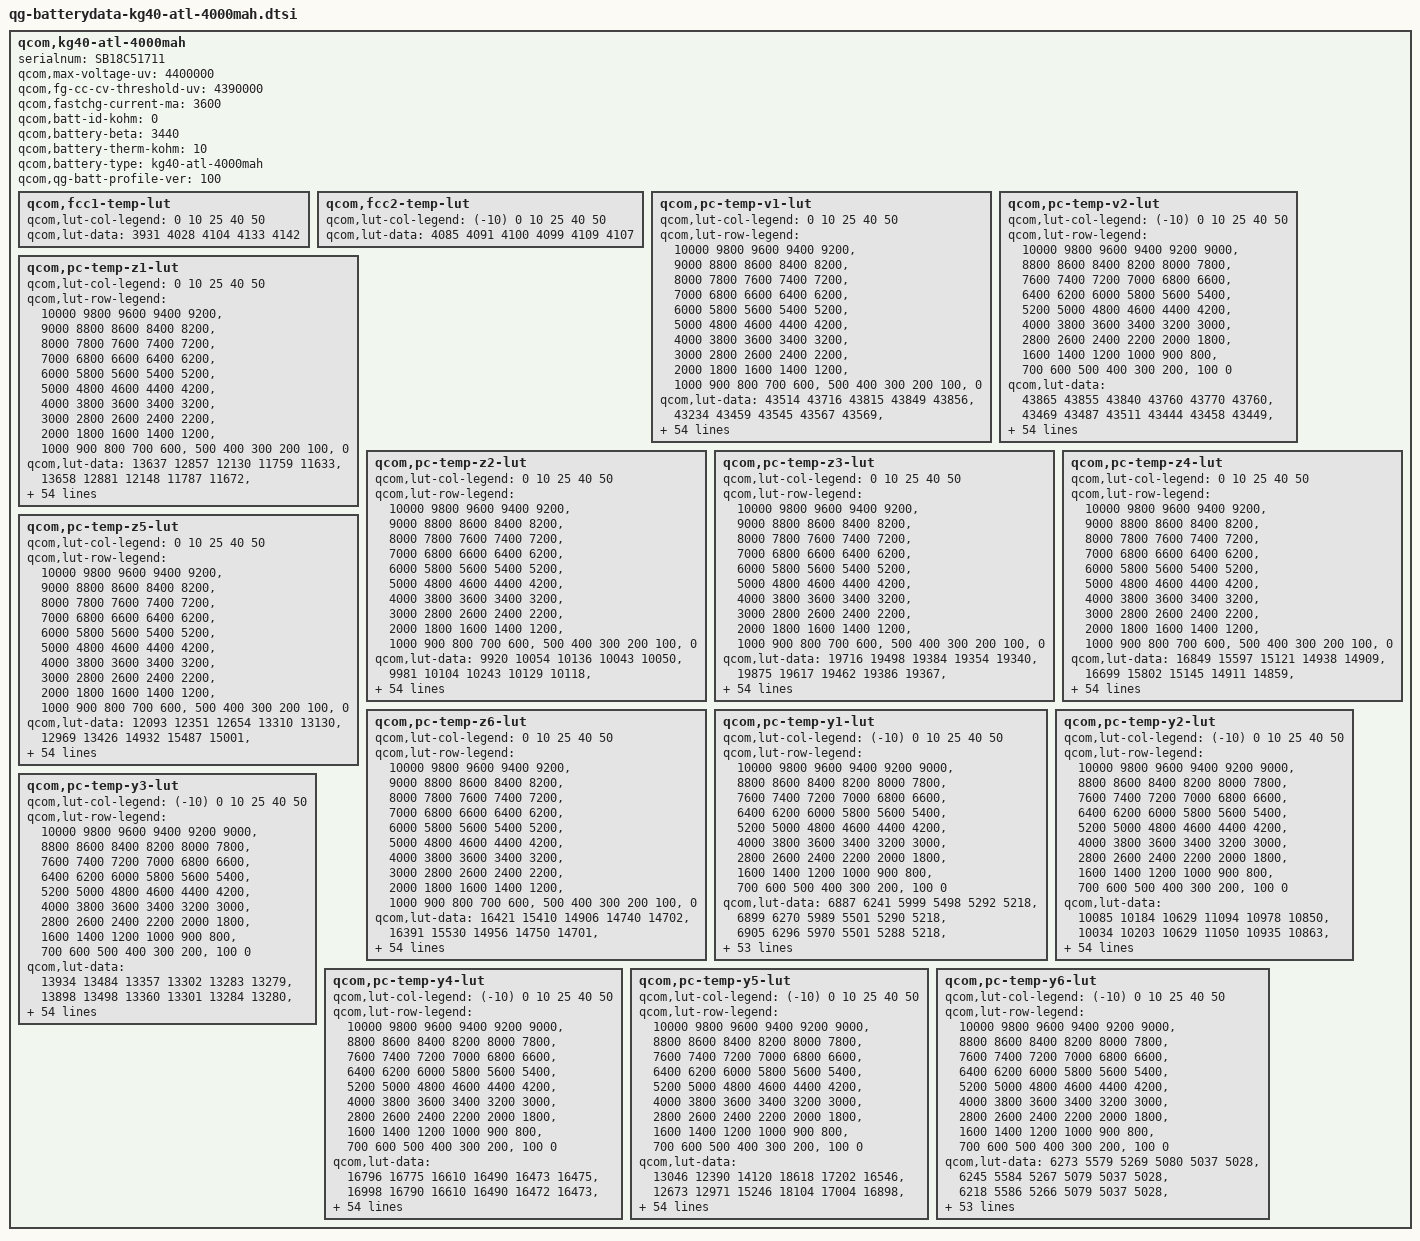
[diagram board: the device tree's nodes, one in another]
qcom,kg40-atl-4000mah {
    /* 4123835_Huaqin_QL1883_ATL_4000mAH_PMI632_averaged_MasterSlave_Aug13th2019 */
    serialnum = "SB18C51711";
    qcom,max-voltage-uv = <4400000>;
    qcom,fg-cc-cv-threshold-uv = <4390000>;
    qcom,fastchg-current-ma = <3600>;
    qcom,batt-id-kohm = <0>;
    qcom,battery-beta = <3440>;
    qcom,battery-therm-kohm = <10>;
    qcom,battery-type = "kg40-atl-4000mah";
    qcom,qg-batt-profile-ver = <100>;

	qcom,fcc1-temp-lut {
		qcom,lut-col-legend = <0 10 25 40 50>;
		qcom,lut-data = <3931 4028 4104 4133 4142>;
	};

	qcom,fcc2-temp-lut {
		qcom,lut-col-legend = <(-10) 0 10 25 40 50>;
		qcom,lut-data = <4085 4091 4100 4099 4109 4107>;
	};

	qcom,pc-temp-v1-lut {
		qcom,lut-col-legend = <0 10 25 40 50>;
		qcom,lut-row-legend = <10000 9800 9600 9400 9200>,
			<9000 8800 8600 8400 8200>,
			<8000 7800 7600 7400 7200>,
			<7000 6800 6600 6400 6200>,
			<6000 5800 5600 5400 5200>,
			<5000 4800 4600 4400 4200>,
			<4000 3800 3600 3400 3200>,
			<3000 2800 2600 2400 2200>,
			<2000 1800 1600 1400 1200>,
			<1000 900 800 700 600>,
			<500 400 300 200 100>,
			<0>;
		qcom,lut-data = <43514 43716 43815 43849 43856>,
			<43234 43459 43545 43567 43569>,
			<42974 43194 43286 43323 43320>,
			<42734 42937 43040 43079 43083>,
			<42503 42695 42797 42835 42850>,
			<42274 42459 42556 42597 42613>,
			<42047 42226 42319 42362 42377>,
			<41826 41997 42085 42129 42144>,
			<41605 41772 41854 41899 41915>,
			<41393 41547 41629 41672 41688>,
			<41204 41330 41406 41446 41463>,
			<41033 41139 41191 41227 41243>,
			<40840 40969 40987 41018 41028>,
			<40580 40774 40789 40820 40820>,
			<40311 40523 40582 40618 40617>,
			<40109 40273 40365 40407 40417>,
			<39945 40088 40168 40206 40226>,
			<39799 39933 40000 40034 40051>,
			<39663 39788 39846 39877 39887>,
			<39536 39654 39701 39723 39730>,
			<39409 39521 39565 39580 39584>,
			<39284 39373 39394 39415 39421>,
			<39160 39217 39128 39165 39182>,
			<39039 39038 38871 38900 38923>,
			<38919 38806 38722 38746 38764>,
			<38795 38605 38612 38645 38660>,
			<38659 38499 38522 38555 38566>,
			<38538 38425 38449 38467 38474>,
			<38447 38366 38385 38386 38388>,
			<38370 38320 38322 38310 38302>,
			<38313 38280 38265 38239 38219>,
			<38268 38241 38212 38173 38147>,
			<38231 38205 38162 38116 38086>,
			<38199 38171 38115 38061 38029>,
			<38172 38140 38075 38011 37974>,
			<38143 38109 38036 37964 37922>,
			<38117 38077 37996 37916 37868>,
			<38085 38043 37955 37871 37815>,
			<38037 37993 37902 37814 37751>,
			<37966 37913 37820 37729 37663>,
			<37878 37814 37719 37625 37557>,
			<37760 37698 37609 37516 37446>,
			<37623 37563 37483 37394 37322>,
			<37471 37405 37327 37238 37166>,
			<37329 37262 37181 37093 37026>,
			<37226 37160 37082 37002 36943>,
			<37193 37131 37054 36971 36915>,
			<37177 37111 37033 36953 36894>,
			<37149 37091 37017 36933 36872>,
			<37105 37051 36975 36877 36805>,
			<36909 36846 36750 36632 36537>,
			<36470 36417 36324 36196 36096>,
			<35894 35844 35752 35620 35518>,
			<35109 35058 34971 34835 34728>,
			<33864 33824 33754 33616 33501>,
			<30000 30000 30000 30000 30000>;
	};

	qcom,pc-temp-v2-lut {
		qcom,lut-col-legend = <(-10) 0 10 25 40 50>;
		qcom,lut-row-legend = <10000 9800 9600 9400 9200 9000>,
			<8800 8600 8400 8200 8000 7800>,
			<7600 7400 7200 7000 6800 6600>,
			<6400 6200 6000 5800 5600 5400>,
			<5200 5000 4800 4600 4400 4200>,
			<4000 3800 3600 3400 3200 3000>,
			<2800 2600 2400 2200 2000 1800>,
			<1600 1400 1200 1000 900 800>,
			<700 600 500 400 300 200>,
			<100 0>;
		qcom,lut-data = <43865 43855 43840 43760 43770 43760>,
			<43469 43487 43511 43444 43458 43449>,
			<43114 43156 43207 43152 43168 43160>,
			<42803 42867 42933 42886 42904 42898>,
			<42528 42616 42686 42645 42663 42659>,
			<42282 42372 42445 42409 42427 42423>,
			<42071 42128 42202 42173 42191 42188>,
			<41868 41889 41965 41940 41957 41955>,
			<41619 41657 41735 41711 41728 41726>,
			<41337 41430 41511 41484 41501 41499>,
			<41120 41218 41296 41264 41278 41276>,
			<40992 41027 41092 41051 41061 41058>,
			<40858 40839 40890 40842 40849 40844>,
			<40597 40639 40685 40636 40645 40641>,
			<40215 40429 40476 40430 40445 40443>,
			<39898 40181 40267 40229 40252 40252>,
			<39645 39854 40058 40028 40061 40066>,
			<39428 39563 39848 39846 39880 39889>,
			<39251 39386 39632 39702 39721 39725>,
			<39097 39247 39417 39571 39568 39566>,
			<38943 39092 39217 39390 39389 39391>,
			<38787 38923 39026 39139 39183 39198>,
			<38640 38767 38855 38911 38983 39006>,
			<38497 38638 38703 38737 38787 38804>,
			<38364 38517 38567 38588 38610 38616>,
			<38264 38385 38446 38464 38477 38480>,
			<38185 38240 38338 38360 38371 38373>,
			<38115 38129 38240 38265 38276 38277>,
			<38051 38055 38150 38175 38190 38190>,
			<37990 37996 38067 38094 38112 38111>,
			<37934 37944 37987 38022 38043 38038>,
			<37882 37898 37913 37954 37978 37969>,
			<37830 37858 37857 37895 37915 37906>,
			<37778 37824 37816 37841 37854 37849>,
			<37725 37788 37780 37791 37790 37787>,
			<37668 37741 37743 37739 37718 37701>,
			<37606 37685 37706 37686 37641 37602>,
			<37543 37627 37664 37628 37562 37508>,
			<37476 37570 37617 37561 37479 37418>,
			<37408 37505 37560 37488 37396 37332>,
			<37341 37427 37477 37407 37317 37252>,
			<37274 37334 37374 37314 37229 37165>,
			<37204 37226 37258 37199 37120 37055>,
			<37134 37108 37123 37066 36988 36923>,
			<37057 36989 36979 36940 36872 36812>,
			<36956 36881 36891 36880 36822 36766>,
			<36905 36840 36864 36862 36809 36753>,
			<36845 36798 36836 36847 36794 36740>,
			<36772 36747 36799 36818 36766 36710>,
			<36659 36671 36728 36738 36680 36605>,
			<36440 36485 36524 36476 36391 36288>,
			<36056 36086 36073 35978 35895 35783>,
			<35473 35476 35371 35342 35248 35131>,
			<34595 34618 34504 34471 34366 34243>,
			<33198 33316 33251 33249 33151 33010>,
			<28298 28054 28063 28066 28079 27986>;
	};

	qcom,pc-temp-z1-lut {
		qcom,lut-col-legend = <0 10 25 40 50>;
		qcom,lut-row-legend = <10000 9800 9600 9400 9200>,
			<9000 8800 8600 8400 8200>,
			<8000 7800 7600 7400 7200>,
			<7000 6800 6600 6400 6200>,
			<6000 5800 5600 5400 5200>,
			<5000 4800 4600 4400 4200>,
			<4000 3800 3600 3400 3200>,
			<3000 2800 2600 2400 2200>,
			<2000 1800 1600 1400 1200>,
			<1000 900 800 700 600>,
			<500 400 300 200 100>,
			<0>;
		qcom,lut-data = <13637 12857 12130 11759 11633>,
			<13658 12881 12148 11787 11672>,
			<13662 12861 12139 11782 11670>,
			<13657 12850 12126 11777 11669>,
			<13653 12843 12114 11773 11669>,
			<13648 12834 12104 11769 11667>,
			<13630 12822 12094 11765 11664>,
			<13621 12797 12085 11764 11664>,
			<13627 12782 12076 11763 11667>,
			<13634 12776 12073 11762 11669>,
			<13627 12772 12073 11762 11669>,
			<13601 12769 12072 11762 11668>,
			<13573 12762 12072 11761 11668>,
			<13539 12754 12071 11761 11668>,
			<13503 12735 12069 11760 11669>,
			<13482 12719 12066 11760 11668>,
			<13468 12721 12064 11759 11668>,
			<13461 12730 12067 11760 11669>,
			<13457 12737 12071 11762 11672>,
			<13452 12744 12075 11765 11674>,
			<13450 12749 12079 11767 11676>,
			<13451 12753 12082 11769 11678>,
			<13455 12759 12084 11770 11679>,
			<13473 12763 12087 11771 11679>,
			<13499 12767 12092 11773 11681>,
			<13509 12772 12098 11777 11683>,
			<13514 12775 12103 11780 11685>,
			<13518 12776 12109 11784 11688>,
			<13523 12780 12114 11788 11692>,
			<13527 12786 12119 11792 11696>,
			<13526 12792 12124 11796 11700>,
			<13528 12794 12129 11801 11704>,
			<13532 12793 12136 11805 11708>,
			<13534 12797 12143 11810 11713>,
			<13539 12804 12149 11815 11718>,
			<13549 12812 12155 11821 11723>,
			<13564 12822 12162 11825 11726>,
			<13580 12836 12170 11829 11728>,
			<13595 12843 12178 11833 11730>,
			<13616 12848 12186 11836 11733>,
			<13632 12853 12193 11840 11737>,
			<13631 12871 12204 11843 11741>,
			<13628 12890 12215 11848 11745>,
			<13631 12895 12218 11853 11748>,
			<13636 12905 12223 11860 11750>,
			<13626 12899 12232 11863 11753>,
			<13650 12879 12233 11862 11753>,
			<13630 12918 12230 11863 11754>,
			<13614 12896 12231 11866 11757>,
			<13636 12907 12241 11871 11762>,
			<13683 12912 12250 11876 11767>,
			<13645 12946 12265 11886 11774>,
			<13664 12980 12283 11900 11788>,
			<13708 13028 12309 11918 11804>,
			<13708 13028 12309 11918 11804>,
			<13708 13028 12309 11918 11804>;
	};

	qcom,pc-temp-z2-lut {
		qcom,lut-col-legend = <0 10 25 40 50>;
		qcom,lut-row-legend = <10000 9800 9600 9400 9200>,
			<9000 8800 8600 8400 8200>,
			<8000 7800 7600 7400 7200>,
			<7000 6800 6600 6400 6200>,
			<6000 5800 5600 5400 5200>,
			<5000 4800 4600 4400 4200>,
			<4000 3800 3600 3400 3200>,
			<3000 2800 2600 2400 2200>,
			<2000 1800 1600 1400 1200>,
			<1000 900 800 700 600>,
			<500 400 300 200 100>,
			<0>;
		qcom,lut-data = <9920 10054 10136 10043 10050>,
			<9981 10104 10243 10129 10118>,
			<10031 10086 10266 10237 10252>,
			<10078 10069 10257 10280 10262>,
			<10109 10048 10245 10299 10263>,
			<10117 10027 10218 10287 10254>,
			<10120 10019 10189 10262 10236>,
			<10120 10013 10166 10243 10221>,
			<10113 10009 10145 10220 10200>,
			<10101 10004 10142 10208 10186>,
			<10091 10001 10157 10213 10156>,
			<10081 10026 10176 10215 10115>,
			<10067 10109 10193 10180 10117>,
			<10023 10146 10209 10102 10137>,
			<9977 10094 10216 10076 10149>,
			<9984 10037 10219 10130 10120>,
			<10043 10044 10222 10179 10091>,
			<10079 10073 10227 10162 10098>,
			<10049 10098 10234 10126 10113>,
			<9999 10119 10246 10120 10128>,
			<9981 10137 10267 10141 10149>,
			<9972 10152 10293 10177 10177>,
			<9968 10164 10337 10289 10249>,
			<9967 10174 10370 10422 10338>,
			<9967 10184 10353 10405 10338>,
			<9969 10191 10307 10260 10265>,
			<9982 10195 10295 10190 10226>,
			<9993 10198 10316 10205 10237>,
			<9998 10198 10333 10232 10260>,
			<10002 10193 10334 10273 10322>,
			<10005 10188 10334 10333 10444>,
			<10010 10189 10337 10356 10479>,
			<10016 10193 10349 10360 10385>,
			<10021 10197 10358 10358 10270>,
			<10027 10204 10360 10338 10192>,
			<10034 10212 10361 10306 10128>,
			<10045 10220 10366 10294 10124>,
			<10056 10227 10379 10299 10175>,
			<10067 10235 10395 10306 10229>,
			<10077 10242 10423 10324 10272>,
			<10089 10250 10446 10346 10305>,
			<10102 10257 10445 10349 10309>,
			<10120 10265 10437 10347 10305>,
			<10152 10277 10437 10383 10319>,
			<10355 10367 10455 10411 10325>,
			<10447 10450 10501 10357 10270>,
			<10434 10469 10494 10327 10287>,
			<10397 10559 10492 10341 10289>,
			<10413 10625 10481 10358 10306>,
			<10454 10627 10532 10440 10367>,
			<10417 10605 10584 10398 10252>,
			<10323 10588 10532 10222 10072>,
			<10117 10479 10437 10136 9996>,
			<9928 10350 10431 10083 9941>,
			<9928 10350 10431 10083 9941>,
			<9928 10350 10431 10083 9941>;
	};

	qcom,pc-temp-z3-lut {
		qcom,lut-col-legend = <0 10 25 40 50>;
		qcom,lut-row-legend = <10000 9800 9600 9400 9200>,
			<9000 8800 8600 8400 8200>,
			<8000 7800 7600 7400 7200>,
			<7000 6800 6600 6400 6200>,
			<6000 5800 5600 5400 5200>,
			<5000 4800 4600 4400 4200>,
			<4000 3800 3600 3400 3200>,
			<3000 2800 2600 2400 2200>,
			<2000 1800 1600 1400 1200>,
			<1000 900 800 700 600>,
			<500 400 300 200 100>,
			<0>;
		qcom,lut-data = <19716 19498 19384 19354 19340>,
			<19875 19617 19462 19386 19367>,
			<19914 19691 19504 19420 19409>,
			<19868 19717 19515 19441 19419>,
			<19812 19714 19518 19450 19424>,
			<19776 19710 19517 19452 19431>,
			<19745 19705 19514 19453 19437>,
			<19735 19696 19511 19451 19438>,
			<19737 19688 19507 19445 19431>,
			<19739 19682 19501 19438 19424>,
			<19740 19677 19486 19432 19418>,
			<19740 19672 19475 19426 19412>,
			<19745 19670 19471 19416 19407>,
			<19780 19669 19468 19401 19404>,
			<19830 19655 19467 19397 19400>,
			<19865 19634 19468 19402 19397>,
			<19894 19611 19467 19407 19393>,
			<19907 19580 19459 19402 19387>,
			<19857 19563 19447 19391 19377>,
			<19783 19555 19440 19383 19370>,
			<19769 19551 19434 19376 19363>,
			<19778 19557 19432 19373 19360>,
			<19786 19576 19450 19381 19364>,
			<19790 19592 19468 19393 19372>,
			<19796 19607 19464 19390 19368>,
			<19803 19616 19451 19369 19347>,
			<19814 19616 19445 19360 19335>,
			<19821 19615 19442 19360 19339>,
			<19818 19612 19440 19361 19346>,
			<19811 19606 19441 19366 19364>,
			<19805 19598 19443 19379 19398>,
			<19794 19592 19445 19390 19409>,
			<19782 19585 19451 19399 19404>,
			<19770 19580 19454 19404 19396>,
			<19756 19576 19454 19402 19388>,
			<19741 19572 19452 19397 19378>,
			<19723 19565 19450 19391 19372>,
			<19707 19558 19445 19383 19367>,
			<19700 19553 19441 19378 19363>,
			<19696 19550 19438 19375 19358>,
			<19691 19547 19435 19373 19355>,
			<19684 19543 19431 19370 19356>,
			<19673 19539 19425 19367 19359>,
			<19647 19532 19423 19371 19367>,
			<19559 19498 19414 19373 19370>,
			<19508 19464 19400 19356 19352>,
			<19498 19453 19394 19355 19343>,
			<19349 19414 19392 19349 19337>,
			<19344 19358 19367 19342 19333>,
			<19336 19378 19359 19336 19332>,
			<19346 19389 19370 19342 19354>,
			<19355 19374 19364 19365 19367>,
			<19362 19351 19364 19368 19370>,
			<19367 19345 19351 19369 19372>,
			<19367 19345 19351 19369 19372>,
			<19367 19345 19351 19369 19372>;
	};

	qcom,pc-temp-z4-lut {
		qcom,lut-col-legend = <0 10 25 40 50>;
		qcom,lut-row-legend = <10000 9800 9600 9400 9200>,
			<9000 8800 8600 8400 8200>,
			<8000 7800 7600 7400 7200>,
			<7000 6800 6600 6400 6200>,
			<6000 5800 5600 5400 5200>,
			<5000 4800 4600 4400 4200>,
			<4000 3800 3600 3400 3200>,
			<3000 2800 2600 2400 2200>,
			<2000 1800 1600 1400 1200>,
			<1000 900 800 700 600>,
			<500 400 300 200 100>,
			<0>;
		qcom,lut-data = <16849 15597 15121 14938 14909>,
			<16699 15802 15145 14911 14859>,
			<16517 15603 15206 14985 14923>,
			<16281 15414 15085 14939 14894>,
			<16052 15276 14994 14885 14856>,
			<15885 15158 14940 14853 14828>,
			<15748 15073 14898 14826 14803>,
			<15629 15005 14862 14802 14782>,
			<15527 14953 14833 14779 14763>,
			<15435 14914 14812 14765 14751>,
			<15350 14879 14796 14757 14746>,
			<15271 14833 14783 14751 14743>,
			<15200 14775 14769 14749 14737>,
			<15140 14752 14756 14746 14729>,
			<15081 14772 14747 14743 14723>,
			<14998 14796 14741 14732 14718>,
			<14884 14796 14734 14720 14713>,
			<14829 14792 14724 14711 14709>,
			<14847 14787 14713 14704 14704>,
			<14874 14771 14706 14701 14701>,
			<14873 14755 14700 14699 14697>,
			<14841 14744 14701 14698 14695>,
			<14813 14736 14767 14753 14745>,
			<14800 14738 14839 14838 14831>,
			<14790 14802 14857 14860 14856>,
			<14789 14863 14867 14866 14863>,
			<14801 14862 14868 14868 14865>,
			<14812 14852 14853 14856 14851>,
			<14817 14840 14832 14835 14823>,
			<14822 14824 14814 14812 14787>,
			<14822 14807 14796 14784 14739>,
			<14816 14793 14777 14759 14715>,
			<14807 14780 14759 14734 14705>,
			<14799 14767 14743 14717 14701>,
			<14791 14755 14730 14710 14701>,
			<14787 14745 14719 14706 14700>,
			<14784 14737 14714 14705 14700>,
			<14782 14731 14710 14705 14700>,
			<14775 14729 14708 14705 14701>,
			<14765 14731 14715 14715 14713>,
			<14760 14732 14721 14728 14730>,
			<14760 14730 14720 14727 14727>,
			<14760 14727 14714 14720 14715>,
			<14763 14725 14713 14718 14712>,
			<14762 14717 14707 14710 14706>,
			<14767 14706 14681 14690 14686>,
			<14777 14710 14678 14684 14685>,
			<14938 14743 14665 14672 14673>,
			<14937 14800 14679 14654 14649>,
			<14938 14770 14681 14653 14641>,
			<14925 14768 14693 14685 14664>,
			<14940 14802 14714 14679 14670>,
			<14951 14837 14722 14680 14672>,
			<14969 14854 14741 14684 14673>,
			<14969 14854 14741 14684 14673>,
			<14969 14854 14741 14684 14673>;
	};

	qcom,pc-temp-z5-lut {
		qcom,lut-col-legend = <0 10 25 40 50>;
		qcom,lut-row-legend = <10000 9800 9600 9400 9200>,
			<9000 8800 8600 8400 8200>,
			<8000 7800 7600 7400 7200>,
			<7000 6800 6600 6400 6200>,
			<6000 5800 5600 5400 5200>,
			<5000 4800 4600 4400 4200>,
			<4000 3800 3600 3400 3200>,
			<3000 2800 2600 2400 2200>,
			<2000 1800 1600 1400 1200>,
			<1000 900 800 700 600>,
			<500 400 300 200 100>,
			<0>;
		qcom,lut-data = <12093 12351 12654 13310 13130>,
			<12969 13426 14932 15487 15001>,
			<13227 14458 15741 15878 16983>,
			<13194 15123 16257 17020 17637>,
			<13163 15442 16621 18115 18105>,
			<13173 15692 16913 18550 18998>,
			<13213 16011 17205 18846 19992>,
			<13261 16367 17620 19106 20468>,
			<13380 16784 18082 19427 20753>,
			<13524 17458 18245 19586 20885>,
			<13610 18064 18246 19735 20781>,
			<13696 18218 18275 19799 20670>,
			<13857 18274 18647 19281 20900>,
			<14557 18440 19343 18248 21371>,
			<15757 19772 19999 18014 21894>,
			<17422 21116 20700 19927 22742>,
			<20012 20497 21239 21817 23430>,
			<21355 18511 21639 21987 23239>,
			<19807 17762 22072 21837 22663>,
			<17469 18300 22678 21981 22506>,
			<17275 19388 23813 22265 22756>,
			<18927 22541 26024 22744 23168>,
			<21004 29413 36255 25704 24161>,
			<23157 35883 45752 29567 25405>,
			<25990 43009 42174 28416 24421>,
			<29841 47676 31641 21465 18772>,
			<36608 46180 26136 17467 15562>,
			<41902 41642 23773 16631 15324>,
			<42493 37881 22617 16227 15218>,
			<41188 34834 22445 16559 16795>,
			<39462 32444 22443 17797 21656>,
			<37013 30832 22892 19446 24573>,
			<34356 29619 24990 22230 25951>,
			<32102 29327 27334 24968 26686>,
			<29927 29423 29634 27092 26841>,
			<27798 29497 31701 28799 26915>,
			<25272 29152 32555 28975 26904>,
			<23535 28486 33059 28276 26856>,
			<23746 28225 33190 27344 26755>,
			<24683 28341 32153 26165 24895>,
			<25192 28353 30364 24671 22301>,
			<25285 27871 28104 22689 21475>,
			<25162 27189 25680 20617 21114>,
			<23356 26485 25130 21603 22764>,
			<20381 24508 24623 22471 24060>,
			<18034 22141 24703 19962 20088>,
			<17562 20154 23046 19951 17960>,
			<12058 15796 23408 19357 17858>,
			<11979 13106 17961 20069 19972>,
			<11907 14047 17176 19187 21295>,
			<12188 14740 17659 16669 20488>,
			<12165 13503 15607 17584 19434>,
			<12056 12586 14938 17202 18529>,
			<11882 12243 13660 16338 17231>,
			<11882 12243 13660 16338 17231>,
			<11882 12243 13660 16338 17231>;
	};

	qcom,pc-temp-z6-lut {
		qcom,lut-col-legend = <0 10 25 40 50>;
		qcom,lut-row-legend = <10000 9800 9600 9400 9200>,
			<9000 8800 8600 8400 8200>,
			<8000 7800 7600 7400 7200>,
			<7000 6800 6600 6400 6200>,
			<6000 5800 5600 5400 5200>,
			<5000 4800 4600 4400 4200>,
			<4000 3800 3600 3400 3200>,
			<3000 2800 2600 2400 2200>,
			<2000 1800 1600 1400 1200>,
			<1000 900 800 700 600>,
			<500 400 300 200 100>,
			<0>;
		qcom,lut-data = <16421 15410 14906 14740 14702>,
			<16391 15530 14956 14750 14701>,
			<16329 15470 15001 14797 14748>,
			<16181 15403 14954 14786 14740>,
			<16016 15335 14916 14773 14730>,
			<15907 15268 14890 14761 14722>,
			<15817 15218 14868 14749 14715>,
			<15746 15177 14850 14737 14707>,
			<15692 15145 14834 14725 14697>,
			<15646 15120 14819 14715 14688>,
			<15599 15098 14805 14708 14682>,
			<15554 15071 14794 14702 14677>,
			<15520 15041 14784 14694 14671>,
			<15500 15026 14777 14686 14665>,
			<15483 15022 14772 14680 14660>,
			<15460 15018 14769 14678 14656>,
			<15430 15009 14765 14675 14652>,
			<15402 14993 14756 14669 14646>,
			<15377 14979 14746 14660 14639>,
			<15357 14969 14739 14654 14633>,
			<15347 14962 14734 14649 14628>,
			<15340 14963 14734 14647 14625>,
			<15338 14971 14773 14677 14650>,
			<15338 14983 14814 14720 14691>,
			<15340 15019 14816 14726 14698>,
			<15343 15050 14816 14720 14693>,
			<15356 15051 14816 14714 14687>,
			<15368 15047 14809 14709 14681>,
			<15370 15043 14800 14703 14675>,
			<15370 15034 14794 14698 14672>,
			<15368 15024 14788 14693 14669>,
			<15362 15016 14782 14688 14665>,
			<15355 15009 14778 14684 14659>,
			<15348 15003 14774 14679 14653>,
			<15340 14998 14770 14675 14649>,
			<15333 14993 14766 14672 14645>,
			<15326 14989 14762 14668 14641>,
			<15321 14986 14759 14664 14638>,
			<15320 14985 14758 14662 14636>,
			<15319 14988 14761 14665 14640>,
			<15319 14990 14763 14669 14644>,
			<15322 14991 14762 14668 14644>,
			<15323 14992 14758 14664 14642>,
			<15317 14992 14758 14666 14644>,
			<15286 14980 14753 14664 14644>,
			<15268 14962 14737 14647 14626>,
			<15265 14957 14733 14644 14622>,
			<15257 14952 14727 14636 14613>,
			<15256 14949 14719 14625 14600>,
			<15258 14950 14718 14621 14596>,
			<15266 14958 14731 14639 14619>,
			<15284 14974 14741 14652 14632>,
			<15308 14987 14749 14658 14638>,
			<15345 15009 14758 14664 14644>,
			<15345 15009 14758 14664 14644>,
			<15345 15009 14758 14664 14644>;
	};

	qcom,pc-temp-y1-lut {
		qcom,lut-col-legend = <(-10) 0 10 25 40 50>;
		qcom,lut-row-legend = <10000 9800 9600 9400 9200 9000>,
			<8800 8600 8400 8200 8000 7800>,
			<7600 7400 7200 7000 6800 6600>,
			<6400 6200 6000 5800 5600 5400>,
			<5200 5000 4800 4600 4400 4200>,
			<4000 3800 3600 3400 3200 3000>,
			<2800 2600 2400 2200 2000 1800>,
			<1600 1400 1200 1000 900 800>,
			<700 600 500 400 300 200>,
			<100 0>;
		qcom,lut-data = <6887 6241 5999 5498 5292 5218>,
			<6899 6270 5989 5501 5290 5218>,
			<6905 6296 5970 5501 5288 5218>,
			<6906 6316 5948 5499 5286 5218>,
			<6905 6330 5931 5496 5284 5218>,
			<6904 6334 5925 5491 5282 5217>,
			<6895 6326 5925 5484 5280 5216>,
			<6884 6317 5926 5477 5277 5215>,
			<6883 6319 5925 5475 5276 5215>,
			<6882 6332 5924 5473 5275 5216>,
			<6876 6335 5921 5472 5275 5216>,
			<6855 6324 5915 5470 5274 5216>,
			<6835 6314 5910 5469 5273 5216>,
			<6846 6322 5911 5468 5273 5215>,
			<6876 6340 5915 5467 5272 5215>,
			<6886 6346 5916 5468 5273 5215>,
			<6883 6345 5912 5470 5273 5216>,
			<6879 6343 5911 5472 5274 5217>,
			<6873 6344 5915 5472 5275 5217>,
			<6865 6346 5921 5472 5275 5218>,
			<6863 6347 5922 5472 5276 5218>,
			<6865 6354 5920 5475 5277 5219>,
			<6863 6358 5919 5479 5278 5219>,
			<6860 6355 5918 5483 5280 5220>,
			<6856 6350 5918 5487 5282 5222>,
			<6853 6348 5921 5491 5284 5224>,
			<6847 6347 5929 5494 5287 5227>,
			<6843 6346 5935 5498 5290 5230>,
			<6840 6351 5941 5504 5294 5232>,
			<6837 6357 5945 5510 5298 5235>,
			<6836 6357 5945 5517 5302 5238>,
			<6840 6350 5943 5524 5307 5241>,
			<6844 6345 5943 5530 5310 5244>,
			<6848 6342 5946 5534 5313 5247>,
			<6851 6339 5948 5537 5316 5250>,
			<6852 6337 5949 5541 5319 5252>,
			<6847 6337 5953 5544 5322 5253>,
			<6844 6337 5955 5548 5324 5255>,
			<6825 6345 5958 5552 5326 5257>,
			<6808 6350 5961 5556 5327 5258>,
			<6811 6328 5968 5559 5329 5258>,
			<6818 6302 5975 5563 5330 5259>,
			<6812 6322 5962 5569 5332 5262>,
			<6813 6339 5966 5577 5335 5264>,
			<6849 6346 5981 5587 5341 5269>,
			<6874 6338 5990 5595 5347 5273>,
			<6906 6338 5995 5598 5349 5274>,
			<6837 6358 5982 5602 5348 5273>,
			<6855 6350 5995 5607 5347 5272>,
			<6855 6332 6004 5607 5347 5273>,
			<6839 6349 6006 5605 5351 5276>,
			<6867 6358 6002 5626 5360 5283>,
			<6946 6371 6030 5656 5372 5293>,
			<7104 6392 6055 5691 5386 5306>,
			<7104 6392 6055 5691 5386 5306>,
			<7104 6392 6055 5691 5386 5306>;
	};

	qcom,pc-temp-y2-lut {
		qcom,lut-col-legend = <(-10) 0 10 25 40 50>;
		qcom,lut-row-legend = <10000 9800 9600 9400 9200 9000>,
			<8800 8600 8400 8200 8000 7800>,
			<7600 7400 7200 7000 6800 6600>,
			<6400 6200 6000 5800 5600 5400>,
			<5200 5000 4800 4600 4400 4200>,
			<4000 3800 3600 3400 3200 3000>,
			<2800 2600 2400 2200 2000 1800>,
			<1600 1400 1200 1000 900 800>,
			<700 600 500 400 300 200>,
			<100 0>;
		qcom,lut-data = <10085 10184 10629 11094 10978 10850>,
			<10034 10203 10629 11050 10935 10863>,
			<10013 10221 10625 11004 10893 10861>,
			<10016 10238 10619 10959 10853 10845>,
			<10035 10254 10611 10921 10818 10821>,
			<10062 10266 10603 10895 10790 10792>,
			<10104 10276 10591 10876 10768 10739>,
			<10165 10285 10581 10862 10750 10694>,
			<10262 10296 10583 10849 10734 10696>,
			<10405 10308 10594 10835 10718 10712>,
			<10457 10336 10602 10828 10717 10717>,
			<10425 10489 10605 10831 10769 10699>,
			<10392 10630 10610 10840 10823 10682>,
			<10431 10632 10660 10860 10829 10687>,
			<10543 10619 10767 10897 10826 10706>,
			<10620 10616 10810 10932 10841 10733>,
			<10671 10627 10819 10962 10898 10783>,
			<10698 10647 10828 11001 10969 10841>,
			<10420 10683 10845 11082 11044 10893>,
			<9869 10739 10866 11175 11118 10956>,
			<9718 10792 10883 11186 11162 11072>,
			<9707 10851 10898 11145 11196 11289>,
			<9699 10879 10912 11113 11207 11394>,
			<9691 10864 10930 11103 11119 11210>,
			<9684 10840 10950 11098 11012 10979>,
			<9679 10831 10972 11107 11006 10965>,
			<9675 10828 11002 11146 11023 11003>,
			<9673 10824 11019 11171 11040 11046>,
			<9671 10816 11026 11183 11079 11120>,
			<9670 10806 11030 11192 11131 11181>,
			<9669 10790 11029 11200 11188 11167>,
			<9668 10763 11027 11215 11253 11126>,
			<9667 10736 11023 11224 11277 11127>,
			<9666 10715 11013 11229 11281 11229>,
			<9665 10684 11000 11231 11279 11307>,
			<9664 10420 10984 11223 11265 11236>,
			<9663 9880 10962 11199 11238 11096>,
			<9663 9702 10942 11177 11192 11033>,
			<9662 9688 10923 11143 11097 11004>,
			<9662 9679 10900 11121 11046 10987>,
			<9661 9673 10866 11110 11054 10986>,
			<9661 9669 10821 11094 11060 10982>,
			<9660 9666 10766 11072 11035 10936>,
			<9660 9663 10690 11029 10986 10885>,
			<9660 9663 10444 11047 10940 10838>,
			<9659 9661 10534 10966 10842 10690>,
			<9659 9659 10494 10959 10833 10688>,
			<9658 9658 10442 10961 10857 10747>,
			<9658 9658 10417 10961 10874 10778>,
			<9657 9657 10321 10964 10874 10755>,
			<9656 9656 9895 10912 10859 10695>,
			<9655 9655 9688 10845 10819 10627>,
			<9652 9654 9664 10757 10705 10532>,
			<9649 9652 9657 10682 10607 10432>,
			<9649 9652 9657 10682 10607 10432>,
			<9649 9652 9657 10682 10607 10432>;
	};

	qcom,pc-temp-y3-lut {
		qcom,lut-col-legend = <(-10) 0 10 25 40 50>;
		qcom,lut-row-legend = <10000 9800 9600 9400 9200 9000>,
			<8800 8600 8400 8200 8000 7800>,
			<7600 7400 7200 7000 6800 6600>,
			<6400 6200 6000 5800 5600 5400>,
			<5200 5000 4800 4600 4400 4200>,
			<4000 3800 3600 3400 3200 3000>,
			<2800 2600 2400 2200 2000 1800>,
			<1600 1400 1200 1000 900 800>,
			<700 600 500 400 300 200>,
			<100 0>;
		qcom,lut-data = <13934 13484 13357 13302 13283 13279>,
			<13898 13498 13360 13301 13284 13280>,
			<13852 13506 13363 13301 13284 13281>,
			<13806 13510 13366 13301 13285 13282>,
			<13772 13512 13368 13301 13285 13283>,
			<13760 13512 13370 13302 13286 13284>,
			<13767 13504 13370 13303 13287 13285>,
			<13775 13494 13370 13305 13288 13285>,
			<13752 13499 13370 13306 13289 13286>,
			<13667 13518 13372 13306 13290 13287>,
			<13601 13524 13373 13307 13292 13288>,
			<13558 13484 13376 13311 13295 13289>,
			<13533 13444 13378 13314 13298 13290>,
			<13536 13445 13376 13315 13300 13293>,
			<13545 13454 13371 13316 13301 13296>,
			<13543 13455 13368 13315 13302 13297>,
			<13493 13439 13368 13311 13303 13297>,
			<13450 13423 13367 13308 13304 13297>,
			<13449 13415 13363 13310 13302 13297>,
			<13449 13409 13357 13315 13298 13297>,
			<13450 13401 13351 13315 13295 13296>,
			<13455 13389 13345 13310 13294 13294>,
			<13458 13379 13341 13305 13292 13291>,
			<13454 13375 13336 13301 13288 13286>,
			<13447 13372 13332 13298 13284 13281>,
			<13445 13367 13330 13298 13283 13280>,
			<13449 13361 13328 13298 13282 13280>,
			<13454 13356 13328 13298 13282 13281>,
			<13462 13354 13328 13297 13283 13282>,
			<13473 13352 13328 13296 13283 13283>,
			<13489 13353 13327 13296 13283 13282>,
			<13511 13354 13324 13297 13284 13280>,
			<13535 13357 13323 13297 13285 13279>,
			<13557 13361 13324 13298 13286 13282>,
			<13581 13368 13326 13299 13286 13284>,
			<13605 13377 13328 13300 13286 13283>,
			<13630 13389 13329 13300 13287 13282>,
			<13659 13402 13332 13300 13286 13282>,
			<13693 13415 13336 13300 13286 13283>,
			<13729 13430 13338 13299 13285 13284>,
			<13767 13449 13338 13300 13286 13285>,
			<13807 13474 13337 13301 13288 13286>,
			<13851 13515 13340 13302 13288 13286>,
			<13895 13566 13340 13300 13285 13283>,
			<13843 13551 13327 13297 13285 13283>,
			<13919 13642 13341 13301 13290 13289>,
			<13981 13716 13349 13302 13293 13291>,
			<14047 13787 13357 13310 13298 13296>,
			<14123 13864 13369 13316 13301 13298>,
			<14213 13943 13384 13318 13301 13296>,
			<14337 14018 13405 13315 13297 13291>,
			<14568 14134 13465 13314 13297 13292>,
			<15261 14355 13614 13325 13301 13298>,
			<17421 14883 13863 13339 13310 13307>,
			<17421 14883 13863 13339 13310 13307>,
			<17421 14883 13863 13339 13310 13307>;
	};

	qcom,pc-temp-y4-lut {
		qcom,lut-col-legend = <(-10) 0 10 25 40 50>;
		qcom,lut-row-legend = <10000 9800 9600 9400 9200 9000>,
			<8800 8600 8400 8200 8000 7800>,
			<7600 7400 7200 7000 6800 6600>,
			<6400 6200 6000 5800 5600 5400>,
			<5200 5000 4800 4600 4400 4200>,
			<4000 3800 3600 3400 3200 3000>,
			<2800 2600 2400 2200 2000 1800>,
			<1600 1400 1200 1000 900 800>,
			<700 600 500 400 300 200>,
			<100 0>;
		qcom,lut-data = <16796 16775 16610 16490 16473 16475>,
			<16998 16790 16610 16490 16472 16473>,
			<17124 16804 16611 16491 16472 16471>,
			<17191 16817 16613 16493 16472 16470>,
			<17218 16830 16614 16494 16473 16469>,
			<17221 16841 16616 16496 16473 16469>,
			<17158 16854 16618 16498 16474 16470>,
			<17080 16864 16621 16501 16476 16471>,
			<17089 16853 16626 16505 16479 16472>,
			<17158 16816 16635 16513 16483 16474>,
			<17239 16807 16645 16520 16485 16477>,
			<17353 16930 16654 16523 16486 16480>,
			<17438 17053 16666 16527 16487 16484>,
			<17325 17048 16702 16537 16491 16486>,
			<17027 17010 16759 16557 16500 16489>,
			<16910 16952 16773 16576 16508 16493>,
			<16892 16823 16756 16598 16515 16500>,
			<16885 16732 16730 16619 16525 16509>,
			<16894 16731 16688 16642 16555 16528>,
			<16913 16734 16635 16662 16590 16549>,
			<16910 16731 16601 16653 16592 16553>,
			<16858 16712 16577 16582 16572 16550>,
			<16808 16690 16562 16524 16546 16546>,
			<16781 16673 16554 16500 16508 16514>,
			<16761 16656 16549 16485 16475 16476>,
			<16758 16627 16547 16483 16472 16472>,
			<16761 16583 16546 16484 16475 16473>,
			<16762 16563 16545 16485 16479 16474>,
			<16763 16566 16539 16490 16486 16479>,
			<16764 16571 16531 16498 16495 16486>,
			<16763 16576 16526 16503 16505 16497>,
			<16757 16583 16522 16509 16514 16511>,
			<16754 16590 16522 16513 16518 16520>,
			<16753 16595 16528 16516 16520 16526>,
			<16753 16603 16538 16517 16521 16529>,
			<16754 16627 16548 16516 16514 16520>,
			<16757 16667 16560 16514 16500 16501>,
			<16759 16688 16571 16511 16490 16489>,
			<16761 16696 16583 16507 16483 16479>,
			<16764 16701 16590 16504 16480 16476>,
			<16772 16701 16590 16506 16485 16483>,
			<16784 16701 16589 16507 16489 16488>,
			<16803 16692 16583 16505 16488 16487>,
			<16811 16684 16574 16500 16477 16473>,
			<16769 16664 16566 16478 16456 16452>,
			<16777 16675 16562 16490 16466 16463>,
			<16788 16686 16577 16505 16484 16491>,
			<16807 16709 16601 16520 16511 16526>,
			<16824 16742 16634 16548 16550 16562>,
			<16838 16782 16683 16572 16557 16557>,
			<16830 16800 16721 16552 16502 16497>,
			<16811 16766 16735 16524 16480 16480>,
			<16891 16747 16767 16546 16486 16482>,
			<17412 16793 16803 16592 16516 16511>,
			<17412 16793 16803 16592 16516 16511>,
			<17412 16793 16803 16592 16516 16511>;
	};

	qcom,pc-temp-y5-lut {
		qcom,lut-col-legend = <(-10) 0 10 25 40 50>;
		qcom,lut-row-legend = <10000 9800 9600 9400 9200 9000>,
			<8800 8600 8400 8200 8000 7800>,
			<7600 7400 7200 7000 6800 6600>,
			<6400 6200 6000 5800 5600 5400>,
			<5200 5000 4800 4600 4400 4200>,
			<4000 3800 3600 3400 3200 3000>,
			<2800 2600 2400 2200 2000 1800>,
			<1600 1400 1200 1000 900 800>,
			<700 600 500 400 300 200>,
			<100 0>;
		qcom,lut-data = <13046 12390 14120 18618 17202 16546>,
			<12673 12971 15246 18104 17004 16898>,
			<12505 13605 16024 17530 16807 17098>,
			<12512 14181 16508 16972 16612 17174>,
			<12664 14590 16752 16506 16421 17156>,
			<12953 14723 16807 16209 16237 17070>,
			<14810 14588 16498 16054 16067 16860>,
			<16916 14425 16080 15914 15889 16583>,
			<16347 14818 15927 15553 15621 16343>,
			<13809 16107 15837 14907 15284 16102>,
			<12765 16555 15754 14688 15224 15843>,
			<13638 14970 15584 14985 15947 15489>,
			<15214 13394 15454 15273 16610 15252>,
			<17954 15436 15618 14996 16275 15522>,
			<21878 20492 16175 14321 15521 16117>,
			<22720 21802 17278 14129 15325 16216>,
			<18845 19113 20654 14295 15358 15685>,
			<15226 16920 23032 14623 15382 15091>,
			<14542 17335 22870 16796 15000 14642>,
			<14173 18177 22436 20527 14387 14287>,
			<14155 18412 21926 22450 15136 14977>,
			<14462 18436 21152 23643 19063 18483>,
			<14676 18478 20423 24107 21190 20424>,
			<14086 19943 19462 22379 20238 19546>,
			<13114 22041 18558 20012 18730 18219>,
			<12818 21830 18474 19672 17670 17433>,
			<12703 19473 18637 19798 16745 16740>,
			<12659 17705 18944 19830 16374 16480>,
			<12648 16844 20443 19356 16297 16509>,
			<12636 16314 21924 18826 16299 16537>,
			<12698 16290 21206 18935 16561 16150>,
			<12947 16371 19088 19500 17207 15319>,
			<13182 16556 18396 20155 17862 15261>,
			<13403 17622 18730 21322 18531 17054>,
			<13555 18609 19063 22139 19277 18837>,
			<13511 17555 19171 22121 20440 19659>,
			<13360 15003 19265 22005 21644 20287>,
			<13273 14251 19516 21705 21530 20343>,
			<13158 14462 20237 20690 19797 19993>,
			<13035 14624 20685 19776 18639 19709>,
			<12922 14537 19856 19198 18484 19632>,
			<12801 14387 18984 18894 18518 19675>,
			<12722 14270 18924 19284 19544 20810>,
			<12836 14013 18278 18238 18017 19151>,
			<13183 13568 15277 18756 18364 18434>,
			<13248 13403 16608 17485 16778 17403>,
			<13501 13746 17014 16371 16585 16178>,
			<13618 13872 16890 17486 16970 16288>,
			<13961 14061 17302 18119 16614 15887>,
			<14431 14419 17410 17864 16289 15281>,
			<14502 14379 15469 17499 17701 15716>,
			<14042 14119 13886 18210 18801 16655>,
			<12618 13629 13782 19719 19221 18079>,
			<10700 13194 13846 22127 23735 23958>,
			<10700 13194 13846 22127 23735 23958>,
			<10700 13194 13846 22127 23735 23958>;
	};

	qcom,pc-temp-y6-lut {
		qcom,lut-col-legend = <(-10) 0 10 25 40 50>;
		qcom,lut-row-legend = <10000 9800 9600 9400 9200 9000>,
			<8800 8600 8400 8200 8000 7800>,
			<7600 7400 7200 7000 6800 6600>,
			<6400 6200 6000 5800 5600 5400>,
			<5200 5000 4800 4600 4400 4200>,
			<4000 3800 3600 3400 3200 3000>,
			<2800 2600 2400 2200 2000 1800>,
			<1600 1400 1200 1000 900 800>,
			<700 600 500 400 300 200>,
			<100 0>;
		qcom,lut-data = <6273 5579 5269 5080 5037 5028>,
			<6245 5584 5267 5079 5037 5028>,
			<6218 5586 5266 5079 5037 5028>,
			<6194 5586 5264 5079 5037 5028>,
			<6171 5584 5262 5079 5038 5029>,
			<6152 5582 5259 5079 5039 5029>,
			<6138 5575 5256 5080 5040 5030>,
			<6124 5567 5254 5082 5041 5031>,
			<6098 5563 5254 5083 5042 5033>,
			<6062 5560 5254 5085 5044 5034>,
			<6048 5559 5255 5088 5046 5036>,
			<6055 5565 5257 5091 5048 5037>,
			<6063 5571 5260 5094 5051 5039>,
			<6041 5571 5267 5099 5054 5041>,
			<5980 5567 5278 5104 5056 5044>,
			<5940 5557 5280 5109 5059 5047>,
			<5916 5516 5275 5112 5062 5049>,
			<5901 5483 5268 5116 5066 5051>,
			<5897 5480 5254 5124 5072 5056>,
			<5895 5479 5234 5133 5079 5062>,
			<5890 5476 5220 5130 5078 5062>,
			<5882 5467 5209 5106 5071 5060>,
			<5876 5463 5203 5086 5062 5056>,
			<5874 5463 5199 5077 5048 5042>,
			<5873 5464 5197 5071 5036 5028>,
			<5875 5463 5197 5071 5035 5027>,
			<5889 5459 5198 5071 5035 5027>,
			<5905 5457 5199 5073 5036 5028>,
			<5920 5467 5201 5074 5039 5031>,
			<5936 5484 5203 5076 5042 5034>,
			<5954 5500 5205 5079 5046 5036>,
			<5976 5518 5206 5081 5049 5039>,
			<5998 5537 5208 5084 5051 5042>,
			<6020 5560 5214 5087 5053 5046>,
			<6043 5584 5223 5089 5053 5048>,
			<6066 5608 5232 5089 5052 5045>,
			<6090 5634 5242 5089 5048 5039>,
			<6116 5663 5255 5090 5046 5036>,
			<6146 5697 5269 5089 5044 5034>,
			<6179 5735 5284 5089 5043 5033>,
			<6213 5775 5297 5090 5045 5037>,
			<6249 5819 5311 5093 5047 5039>,
			<6292 5870 5330 5094 5047 5039>,
			<6334 5928 5349 5093 5043 5033>,
			<6299 5917 5335 5086 5037 5027>,
			<6364 6006 5383 5095 5045 5036>,
			<6417 6077 5416 5102 5052 5046>,
			<6476 6146 5453 5113 5064 5059>,
			<6545 6223 5500 5126 5077 5071>,
			<6628 6304 5557 5134 5079 5068>,
			<6732 6378 5606 5128 5060 5048>,
			<6933 6472 5693 5123 5055 5045>,
			<7590 6660 5918 5147 5062 5051>,
			<9508 7133 6187 5183 5079 5067>,
			<9508 7133 6187 5183 5079 5067>,
			<9508 7133 6187 5183 5079 5067>;
	};

};
